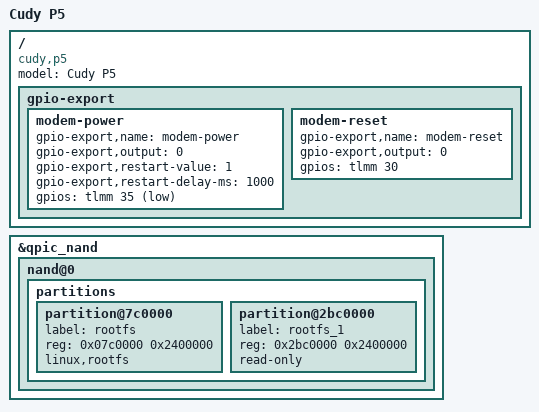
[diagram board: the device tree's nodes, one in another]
// SPDX-License-Identifier: GPL-2.0-or-later OR MIT

/dts-v1/;

#include "ipq5018-cudy-p5.dtsi"

/ {
	model = "Cudy P5";
	compatible = "cudy,p5", "qcom,ipq5018";

	/*
	 * GPIO35 is the active-low modem power line (vendor "5g-power"/"pwr").
	 * gpio-export,output is applied as a raw level: <0> keeps the modem
	 * powered from boot; in sysfs, value 1 = on.
	 *
	 * GPIO30 is an active-high modem reset trigger. A rising edge restarts
	 * the modem, a falling edge causes no observed action.
	 */
	gpio-export {
		modem-power {
			gpio-export,name = "modem-power";
			gpio-export,output = <0>;		/* raw low at boot = modem on */
			gpio-export,restart-value = <1>;	/* raw high before reset = modem off */
			gpio-export,restart-delay-ms = <1000>;
			gpios = <&tlmm 35 GPIO_ACTIVE_LOW>;
		};

		modem-reset {
			gpio-export,name = "modem-reset";
			gpio-export,output = <0>;
			gpios = <&tlmm 30 GPIO_ACTIVE_HIGH>;
		};
	};
};

&qpic_nand {
	nand@0 {
		partitions {
			/*
			 * U-Boot always passes ubi.mtd=rootfs. Expose the physical
			 * rootfs_1 slot as "rootfs" to Linux so the selected OpenWrt
			 * slot is attached as ubi0. The stock slot stays protected.
			 */
			partition@7c0000 {
				label = "rootfs";
				reg = <0x07c0000 0x2400000>;
				linux,rootfs;
			};

			partition@2bc0000 {
				label = "rootfs_1";
				reg = <0x2bc0000 0x2400000>;
				read-only;
			};
		};
	};
};
